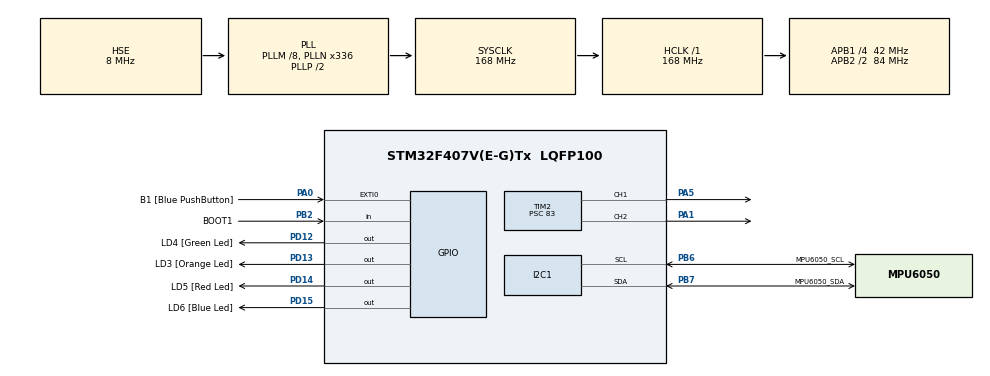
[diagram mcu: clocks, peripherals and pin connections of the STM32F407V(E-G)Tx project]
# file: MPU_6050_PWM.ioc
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I2C1.I2C_Mode=I2C_Standard
Mcu.Family=STM32F4
Mcu.Name=STM32F407V(E-G)Tx
Mcu.Package=LQFP100
NVIC.EXTI0_IRQn=true\:0\:0\:false\:false\:true\:true\:true\:true
NVIC.PriorityGroup=NVIC_PRIORITYGROUP_0
NVIC.TIM2_IRQn=true\:0\:0\:false\:false\:true\:true\:true\:true
PA0-WKUP.GPIO_Label=B1 [Blue PushButton]
PA0-WKUP.GPIO_ModeDefaultEXTI=GPIO_MODE_IT_RISING
PA0-WKUP.GPIO_PuPd=GPIO_NOPULL
PA0-WKUP.Signal=GPXTI0
PA1.Signal=S_TIM2_CH2
PA13.Mode=Serial_Wire
PA13.Signal=SYS_JTMS-SWDIO
PA14.Mode=Serial_Wire
PA14.Signal=SYS_JTCK-SWCLK
PA5.Signal=S_TIM2_CH1_ETR
PB2.GPIO_Label=BOOT1
PB2.GPIO_Mode=GPIO_MODE_INPUT
PB2.GPIO_PuPd=GPIO_NOPULL
PB2.Signal=GPIO_Input
PB3.GPIO_Label=SWO
PB3.Signal=SYS_JTDO-SWO
PB6.GPIO_Label=MPU6050_SCL
PB6.Mode=I2C
PB6.Signal=I2C1_SCL
PB7.GPIO_Label=MPU6050_SDA
PB7.Mode=I2C
PB7.Signal=I2C1_SDA
PD12.GPIO_Label=LD4 [Green Led]
PD12.GPIO_PuPd=GPIO_NOPULL
PD12.GPIO_Speed=GPIO_SPEED_FREQ_LOW
PD12.Signal=GPIO_Output
PD13.GPIO_Label=LD3 [Orange Led]
PD13.GPIO_PuPd=GPIO_NOPULL
PD13.GPIO_Speed=GPIO_SPEED_FREQ_LOW
PD13.Signal=GPIO_Output
PD14.GPIO_Label=LD5 [Red Led]
PD14.GPIO_PuPd=GPIO_NOPULL
PD14.GPIO_Speed=GPIO_SPEED_FREQ_LOW
PD14.Signal=GPIO_Output
PD15.GPIO_Label=LD6 [Blue Led]
PD15.GPIO_PuPd=GPIO_NOPULL
PD15.GPIO_Speed=GPIO_SPEED_FREQ_LOW
PD15.Signal=GPIO_Output
PH0-OSC_IN.Mode=HSE-External-Oscillator
PH0-OSC_IN.Signal=RCC_OSC_IN
PH1-OSC_OUT.Mode=HSE-External-Oscillator
PH1-OSC_OUT.Signal=RCC_OSC_OUT
ProjectManager.HeapSize=0x200
ProjectManager.StackSize=0x400
ProjectManager.TargetToolchain=STM32CubeIDE
RCC.48MHZClocksFreq_Value=48000000
RCC.AHBFreq_Value=168000000
RCC.APB1CLKDivider=RCC_HCLK_DIV4
RCC.APB1Freq_Value=42000000
RCC.APB1TimFreq_Value=84000000
RCC.APB2CLKDivider=RCC_HCLK_DIV2
RCC.APB2Freq_Value=84000000
RCC.APB2TimFreq_Value=168000000
RCC.CortexFreq_Value=168000000
RCC.HCLKFreq_Value=168000000
RCC.HSE_VALUE=8000000
RCC.HSI_VALUE=16000000
RCC.LSE_VALUE=32768
RCC.PLLM=8
RCC.PLLN=336
RCC.PLLQ=7
RCC.PLLSourceVirtual=RCC_PLLSOURCE_HSE
RCC.SYSCLKFreq_VALUE=168000000
RCC.SYSCLKSource=RCC_SYSCLKSOURCE_PLLCLK
RCC.VCOOutputFreq_Value=336000000
SH.S_TIM2_CH1_ETR.0=TIM2_CH1,PWM Generation1 CH1
SH.S_TIM2_CH2.0=TIM2_CH2,PWM Generation2 CH2
TIM2.AutoReloadPreload=TIM_AUTORELOAD_PRELOAD_DISABLE
TIM2.Channel-PWM\ Generation1\ CH1=TIM_CHANNEL_1
TIM2.Channel-PWM\ Generation2\ CH2=TIM_CHANNEL_2
TIM2.Period=999
TIM2.Prescaler=83
TIM2.Pulse-PWM\ Generation1\ CH1=399
TIM2.Pulse-PWM\ Generation2\ CH2=199
TIM2.TIM_MasterOutputTrigger=TIM_TRGO_UPDATE
VP_TIM2_VS_ClockSourceINT.Mode=Internal
board=STM32F407G-DISC1

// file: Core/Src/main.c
/* USER CODE BEGIN Header */
/**
  ******************************************************************************
  * @file           : main.c
  * @brief          : Main program body
  ******************************************************************************
  * @attention
  *
  * Copyright (c) 2025 STMicroelectronics.
  * All rights reserved.
  *
  * This software is licensed under terms that can be found in the LICENSE file
  * in the root directory of this software component.
  * If no LICENSE file comes with this software, it is provided AS-IS.
  *
  ******************************************************************************
  */
/* USER CODE END Header */
#include "main.h"

I2C_HandleTypeDef hi2c1;

TIM_HandleTypeDef htim2;

void SystemClock_Config(void);
static void MX_GPIO_Init(void);
static void MX_I2C1_Init(void);
static void MX_TIM2_Init(void);

int main(void)
{

  /* MCU Configuration--------------------------------------------------------*/

  /* Reset of all peripherals, Initializes the Flash interface and the Systick. */
  HAL_Init();

  /* Configure the system clock */
  SystemClock_Config();

  /* Initialize all configured peripherals */
  MX_GPIO_Init();
  MX_I2C1_Init();
  MX_TIM2_Init();
  /* USER CODE BEGIN 2 */

  if (HAL_TIM_PWM_Start_IT(&htim2,TIM_CHANNEL_1) != HAL_OK ){
	  Error_Handler();
  }
  if (HAL_TIM_PWM_Start_IT(&htim2,TIM_CHANNEL_2) != HAL_OK ){
	  Error_Handler();
  }
  /* USER CODE END 2 */

  /* Infinite loop */
  while (1)
  {

  }
}

void SystemClock_Config(void)
{
  RCC_OscInitTypeDef RCC_OscInitStruct = {0};
  RCC_ClkInitTypeDef RCC_ClkInitStruct = {0};

  /** Configure the main internal regulator output voltage
  */
  __HAL_RCC_PWR_CLK_ENABLE();
  __HAL_PWR_VOLTAGESCALING_CONFIG(PWR_REGULATOR_VOLTAGE_SCALE1);

  /** Initializes the RCC Oscillators according to the specified parameters
  * in the RCC_OscInitTypeDef structure.
  */
  RCC_OscInitStruct.OscillatorType = RCC_OSCILLATORTYPE_HSE;
  RCC_OscInitStruct.HSEState = RCC_HSE_ON;
  RCC_OscInitStruct.PLL.PLLState = RCC_PLL_ON;
  RCC_OscInitStruct.PLL.PLLSource = RCC_PLLSOURCE_HSE;
  RCC_OscInitStruct.PLL.PLLM = 8;
  RCC_OscInitStruct.PLL.PLLN = 336;
  RCC_OscInitStruct.PLL.PLLP = RCC_PLLP_DIV2;
  RCC_OscInitStruct.PLL.PLLQ = 7;
  if (HAL_RCC_OscConfig(&RCC_OscInitStruct) != HAL_OK)
  {
    Error_Handler();
  }

  /** Initializes the CPU, AHB and APB buses clocks
  */
  RCC_ClkInitStruct.ClockType = RCC_CLOCKTYPE_HCLK|RCC_CLOCKTYPE_SYSCLK
                              |RCC_CLOCKTYPE_PCLK1|RCC_CLOCKTYPE_PCLK2;
  RCC_ClkInitStruct.SYSCLKSource = RCC_SYSCLKSOURCE_PLLCLK;
  RCC_ClkInitStruct.AHBCLKDivider = RCC_SYSCLK_DIV1;
  RCC_ClkInitStruct.APB1CLKDivider = RCC_HCLK_DIV4;
  RCC_ClkInitStruct.APB2CLKDivider = RCC_HCLK_DIV2;

  if (HAL_RCC_ClockConfig(&RCC_ClkInitStruct, FLASH_LATENCY_5) != HAL_OK)
  {
    Error_Handler();
  }
}

static void MX_I2C1_Init(void)
{

  hi2c1.Instance = I2C1;
  hi2c1.Init.ClockSpeed = 100000;
  hi2c1.Init.DutyCycle = I2C_DUTYCYCLE_2;
  hi2c1.Init.OwnAddress1 = 0;
  hi2c1.Init.AddressingMode = I2C_ADDRESSINGMODE_7BIT;
  hi2c1.Init.DualAddressMode = I2C_DUALADDRESS_DISABLE;
  hi2c1.Init.OwnAddress2 = 0;
  hi2c1.Init.GeneralCallMode = I2C_GENERALCALL_DISABLE;
  hi2c1.Init.NoStretchMode = I2C_NOSTRETCH_DISABLE;
  if (HAL_I2C_Init(&hi2c1) != HAL_OK)
  {
    Error_Handler();
  }

}

static void MX_TIM2_Init(void)
{

  TIM_ClockConfigTypeDef sClockSourceConfig = {0};
  TIM_MasterConfigTypeDef sMasterConfig = {0};
  TIM_OC_InitTypeDef sConfigOC = {0};

  htim2.Instance = TIM2;
  htim2.Init.Prescaler = 83;
  htim2.Init.CounterMode = TIM_COUNTERMODE_UP;
  htim2.Init.Period = 999;
  htim2.Init.ClockDivision = TIM_CLOCKDIVISION_DIV1;
  htim2.Init.AutoReloadPreload = TIM_AUTORELOAD_PRELOAD_DISABLE;
  if (HAL_TIM_Base_Init(&htim2) != HAL_OK)
  {
    Error_Handler();
  }
  sClockSourceConfig.ClockSource = TIM_CLOCKSOURCE_INTERNAL;
  if (HAL_TIM_ConfigClockSource(&htim2, &sClockSourceConfig) != HAL_OK)
  {
    Error_Handler();
  }
  if (HAL_TIM_PWM_Init(&htim2) != HAL_OK)
  {
    Error_Handler();
  }
  sMasterConfig.MasterOutputTrigger = TIM_TRGO_UPDATE;
  sMasterConfig.MasterSlaveMode = TIM_MASTERSLAVEMODE_DISABLE;
  if (HAL_TIMEx_MasterConfigSynchronization(&htim2, &sMasterConfig) != HAL_OK)
  {
    Error_Handler();
  }
  sConfigOC.OCMode = TIM_OCMODE_PWM1;
  sConfigOC.Pulse = 399;
  sConfigOC.OCPolarity = TIM_OCPOLARITY_HIGH;
  sConfigOC.OCFastMode = TIM_OCFAST_DISABLE;
  if (HAL_TIM_PWM_ConfigChannel(&htim2, &sConfigOC, TIM_CHANNEL_1) != HAL_OK)
  {
    Error_Handler();
  }
  sConfigOC.Pulse = 199;
  if (HAL_TIM_PWM_ConfigChannel(&htim2, &sConfigOC, TIM_CHANNEL_2) != HAL_OK)
  {
    Error_Handler();
  }
  HAL_TIM_MspPostInit(&htim2);

}

static void MX_GPIO_Init(void)
{
  GPIO_InitTypeDef GPIO_InitStruct = {0};

  /* GPIO Ports Clock Enable */
  __HAL_RCC_GPIOH_CLK_ENABLE();
  __HAL_RCC_GPIOA_CLK_ENABLE();
  __HAL_RCC_GPIOB_CLK_ENABLE();
  __HAL_RCC_GPIOD_CLK_ENABLE();

  /*Configure GPIO pin Output Level */
  HAL_GPIO_WritePin(GPIOD, LD4_Pin|LD3_Pin|LD5_Pin|LD6_Pin, GPIO_PIN_RESET);

  /*Configure GPIO pin : B1_Pin */
  GPIO_InitStruct.Pin = B1_Pin;
  GPIO_InitStruct.Mode = GPIO_MODE_IT_RISING;
  GPIO_InitStruct.Pull = GPIO_NOPULL;
  HAL_GPIO_Init(B1_GPIO_Port, &GPIO_InitStruct);

  /*Configure GPIO pin : BOOT1_Pin */
  GPIO_InitStruct.Pin = BOOT1_Pin;
  GPIO_InitStruct.Mode = GPIO_MODE_INPUT;
  GPIO_InitStruct.Pull = GPIO_NOPULL;
  HAL_GPIO_Init(BOOT1_GPIO_Port, &GPIO_InitStruct);

  /*Configure GPIO pins : LD4_Pin LD3_Pin LD5_Pin LD6_Pin */
  GPIO_InitStruct.Pin = LD4_Pin|LD3_Pin|LD5_Pin|LD6_Pin;
  GPIO_InitStruct.Mode = GPIO_MODE_OUTPUT_PP;
  GPIO_InitStruct.Pull = GPIO_NOPULL;
  GPIO_InitStruct.Speed = GPIO_SPEED_FREQ_LOW;
  HAL_GPIO_Init(GPIOD, &GPIO_InitStruct);

  /* EXTI interrupt init*/
  HAL_NVIC_SetPriority(EXTI0_IRQn, 0, 0);
  HAL_NVIC_EnableIRQ(EXTI0_IRQn);

}

void Error_Handler(void)
{
  __disable_irq();
  while (1)
  {
  }
}
